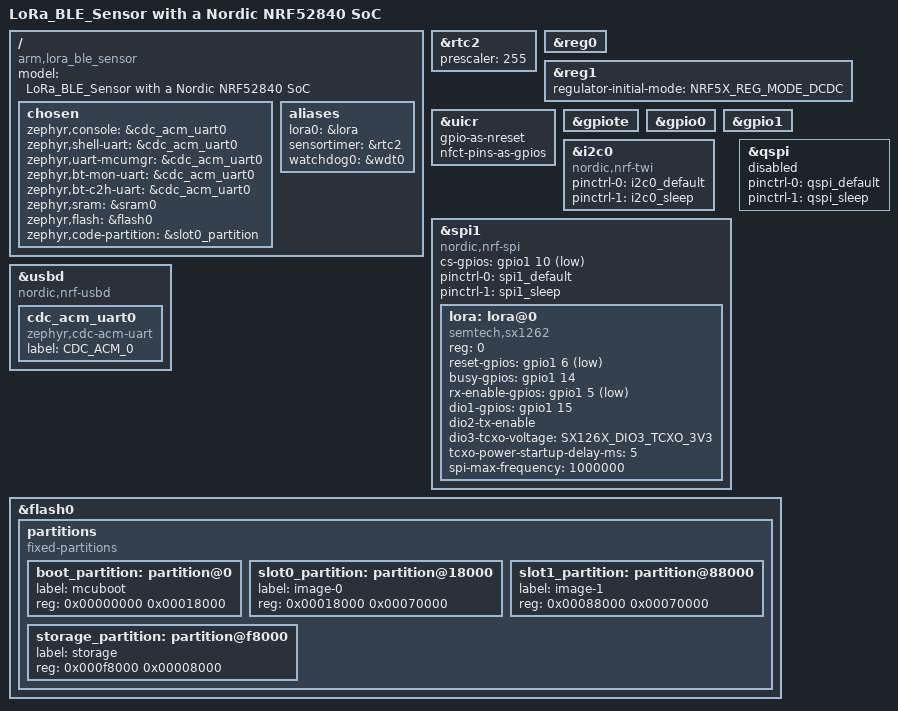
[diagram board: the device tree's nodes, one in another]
/*
 * Copyright (c) 2021 Guillaume Paquet <guillaume.paquet@smile.fr>
 *
 * SPDX-License-Identifier: Apache-2.0
 */

/dts-v1/;
#include <nordic/nrf52840_qiaa.dtsi>
#include <zephyr/dt-bindings/lora/sx126x.h>
#include "lora_ble_sensor-pinctrl.dtsi"
#include <zephyr/dt-bindings/input/input-event-codes.h>

/ {
	model = "LoRa_BLE_Sensor with a Nordic NRF52840 SoC";
	compatible = "arm,lora_ble_sensor";

	chosen {
		zephyr,console = &cdc_acm_uart0;
		zephyr,shell-uart = &cdc_acm_uart0;
		zephyr,uart-mcumgr = &cdc_acm_uart0;
		zephyr,bt-mon-uart = &cdc_acm_uart0;
		zephyr,bt-c2h-uart = &cdc_acm_uart0;
		zephyr,sram = &sram0;
		zephyr,flash = &flash0;
		zephyr,code-partition = &slot0_partition;
	};

	/* Declaration of aliases */
	aliases {
		lora0 = &lora;
		sensortimer = &rtc2;
		watchdog0 = &wdt0;
	};
};

// RTC0 is used by BLE, RTC1 is used for system clock
&rtc2 {
	status = "okay"; 
	prescaler = <255>; // 1 -> 511 seconds; 2 -> 1023 seconds ... 255 -> 36.409 Hours ... 4095 -> 582.542 Hours
};

&reg0 {
	status = "okay";
};

&reg1 {
	regulator-initial-mode = <NRF5X_REG_MODE_DCDC>;
};

&uicr {
	gpio-as-nreset;
	nfct-pins-as-gpios;
};

&gpiote {
	status = "okay";
};

&gpio0 {
	status = "okay";
};

&gpio1 {
	status = "okay";
};

&i2c0 {
	compatible = "nordic,nrf-twi";
	status = "okay";
	pinctrl-0 = <&i2c0_default>;
	pinctrl-1 = <&i2c0_sleep>;
	pinctrl-names = "default", "sleep";
};

&spi1 {
	compatible = "nordic,nrf-spi";
	status = "okay";
	cs-gpios = <&gpio1 10 GPIO_ACTIVE_LOW>;

	pinctrl-0 = <&spi1_default>;
	pinctrl-1 = <&spi1_sleep>;
	pinctrl-names = "default", "sleep";
	lora: lora@0 {
		compatible = "semtech,sx1262";
		reg = <0>;
		reset-gpios = <&gpio1 6 GPIO_ACTIVE_LOW>;
		busy-gpios = <&gpio1 14 GPIO_ACTIVE_HIGH>;
		rx-enable-gpios = <&gpio1 5 GPIO_ACTIVE_LOW>;
		dio1-gpios = <&gpio1 15 GPIO_ACTIVE_HIGH>;
		dio2-tx-enable;
		dio3-tcxo-voltage = <SX126X_DIO3_TCXO_3V3>;
		tcxo-power-startup-delay-ms = <5>;
		spi-max-frequency = <1000000>;
	};
};

&qspi {
	status = "disabled";
	pinctrl-0 = <&qspi_default>;
	pinctrl-1 = <&qspi_sleep>;
	pinctrl-names = "default", "sleep";
};

zephyr_udc0: &usbd {
	compatible = "nordic,nrf-usbd";
	status = "okay";
	cdc_acm_uart0: cdc_acm_uart0 {
		compatible = "zephyr,cdc-acm-uart";
		label = "CDC_ACM_0";
	};
};

&flash0 {
    partitions {
        compatible = "fixed-partitions";
        #address-cells = <1>;
        #size-cells = <1>;

        boot_partition: partition@0 {
            label = "mcuboot";
            reg = <0x00000000 0x00018000>;  /* 96KB was 48KB */
        };

        slot0_partition: partition@18000 {
            label = "image-0";
            reg = <0x00018000 0x00070000>;  /* 448KB was 476KB */
        };

        slot1_partition: partition@88000 {
            label = "image-1";
            reg = <0x00088000 0x00070000>;  /* 448KB was 476KB */
        };

        /*
         * Storage partition will be used by FCB/LittleFS/NVS
         * if enabled.
         */
        storage_partition: partition@f8000 {
            label = "storage";
            reg = <0x000f8000 0x00008000>;  /* 32KB */
        };
    };
};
